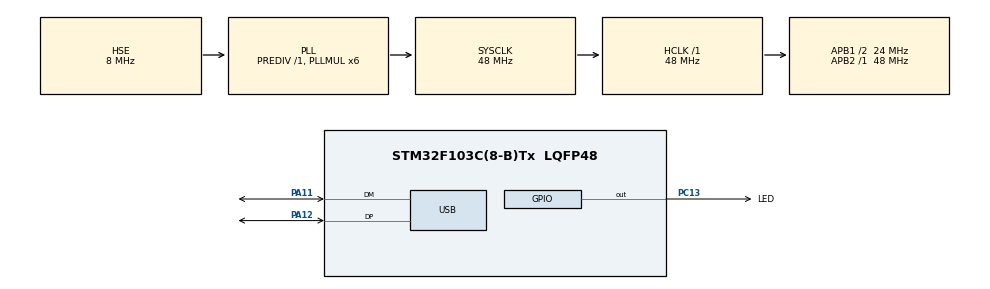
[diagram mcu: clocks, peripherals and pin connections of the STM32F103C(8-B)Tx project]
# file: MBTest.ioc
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Mcu.Family=STM32F1
Mcu.Name=STM32F103C(8-B)Tx
Mcu.Package=LQFP48
NVIC.PriorityGroup=NVIC_PRIORITYGROUP_4
NVIC.TIM4_IRQn=true\:0\:0\:false\:false\:true\:true\:true\:true
NVIC.USB_LP_CAN1_RX0_IRQn=true\:0\:0\:false\:false\:true\:false\:true\:true
PA11.Mode=Device
PA11.Signal=USB_DM
PA12.Mode=Device
PA12.Signal=USB_DP
PA13.Mode=Serial_Wire
PA13.Signal=SYS_JTMS-SWDIO
PA14.Mode=Serial_Wire
PA14.Signal=SYS_JTCK-SWCLK
PC13-TAMPER-RTC.GPIO_Label=LED
PC13-TAMPER-RTC.Signal=GPIO_Output
PC14-OSC32_IN.Mode=LSE-External-Oscillator
PC14-OSC32_IN.Signal=RCC_OSC32_IN
PC15-OSC32_OUT.Mode=LSE-External-Oscillator
PC15-OSC32_OUT.Signal=RCC_OSC32_OUT
PD0-OSC_IN.Mode=HSE-External-Oscillator
PD0-OSC_IN.Signal=RCC_OSC_IN
PD1-OSC_OUT.Mode=HSE-External-Oscillator
PD1-OSC_OUT.Signal=RCC_OSC_OUT
ProjectManager.HeapSize=0x200
ProjectManager.StackSize=0x400
ProjectManager.TargetToolchain=Makefile
RCC.AHBFreq_Value=48000000
RCC.APB1CLKDivider=RCC_HCLK_DIV2
RCC.APB1Freq_Value=24000000
RCC.APB1TimFreq_Value=48000000
RCC.APB2Freq_Value=48000000
RCC.APB2TimFreq_Value=48000000
RCC.HCLKFreq_Value=48000000
RCC.PLLMUL=RCC_PLL_MUL6
RCC.PLLSourceVirtual=RCC_PLLSOURCE_HSE
RCC.SYSCLKFreq_VALUE=48000000
RCC.SYSCLKSource=RCC_SYSCLKSOURCE_PLLCLK
RCC.USBFreq_Value=48000000
TIM4.AutoReloadPreload=TIM_AUTORELOAD_PRELOAD_ENABLE
TIM4.Period=9999
TIM4.Prescaler=47
USB_DEVICE.APP_RX_DATA_SIZE=256
USB_DEVICE.APP_TX_DATA_SIZE=256
USB_DEVICE.CLASS_NAME_FS=CDC
USB_DEVICE.VirtualMode=Cdc
USB_DEVICE.VirtualModeFS=Cdc_FS
VP_TIM4_VS_ClockSourceINT.Mode=Internal
VP_USB_DEVICE_VS_USB_DEVICE_CDC_FS.Mode=CDC_FS
board=custom

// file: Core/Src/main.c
/* USER CODE BEGIN Header */
/**
  ******************************************************************************
  * @file           : main.c
  * @brief          : Main program body
  ******************************************************************************
  * @attention
  *
  * <h2><center>&copy; Copyright (c) 2022 STMicroelectronics.
  * All rights reserved.</center></h2>
  *
  * This software component is licensed by ST under BSD 3-Clause license,
  * the "License"; You may not use this file except in compliance with the
  * License. You may obtain a copy of the License at:
  *                        opensource.org/licenses/BSD-3-Clause
  *
  ******************************************************************************
  */
/* USER CODE END Header */
#include "main.h"
#include "tim.h"
#include "usb_device.h"
#include "gpio.h"

/* USER CODE BEGIN Includes */
#include <string.h>
#include "fifo.h"
#include "mb-rtu.h"
#include "mb-table.h"
#include "usbd_cdc_if.h"
/* USER CODE END Includes */

/* USER CODE BEGIN PTD */

void send_data(uint8_t *Data,uint16_t Len)
{
  CDC_Transmit_FS(Data,Len);
  HAL_GPIO_TogglePin(LED_GPIO_Port,LED_Pin);
}

void add_random_data()
{
  int i;

  mb_table_write(TBALE_Coils,0,rand());
  mb_table_write(TBALE_Discretes_Input,0,rand());

  for(i=0;i<10;i++)
  {
    mb_table_write(TBALE_Input_Registers,i,rand());
  }

  for(i=0;i<10;i++)
  {
    mb_table_write(TABLE_Holding_Registers,i,rand());
  }

}

//Timeout Signal
void HAL_TIM_PeriodElapsedCallback(TIM_HandleTypeDef *htim)
{
  if(htim->Instance==TIM4)
  {
    HAL_TIM_Base_Stop_IT(&htim4);
    mb_rx_timeout_handler();

    //Add Some Data to Table
    add_random_data();
  }
}

void timeout_timer_reset()
{
  //Reset Timer
  TIM4->CNT=0;
  HAL_TIM_Base_Start_IT(&htim4);
}

/* USER CODE END PTD */

void SystemClock_Config(void);

int main(void)
{
  /* USER CODE BEGIN 1 */
  uint8_t Ch;
  /* USER CODE END 1 */

  /* MCU Configuration--------------------------------------------------------*/

  /* Reset of all peripherals, Initializes the Flash interface and the Systick. */
  HAL_Init();

  /* Configure the system clock */
  SystemClock_Config();

  /* USER CODE BEGIN SysInit */
  MX_GPIO_Init();
  /* USER CODE END SysInit */

  /* Initialize all configured peripherals */
  MX_GPIO_Init();
  MX_TIM4_Init();
  MX_USB_DEVICE_Init();
  /* USER CODE BEGIN 2 */
  FIFO_Init(64);
  mb_set_tx_handler(&send_data);
  /* USER CODE END 2 */

  /* Infinite loop */
  /* USER CODE BEGIN WHILE */

  while (1)
  {
    while(FIFO_Read(&Ch)==FIFO_OK)
    {
      mb_rx_new_data(Ch);
      timeout_timer_reset();
    }
    /* USER CODE END WHILE */

  }
}

void SystemClock_Config(void)
{
  RCC_OscInitTypeDef RCC_OscInitStruct = {0};
  RCC_ClkInitTypeDef RCC_ClkInitStruct = {0};
  RCC_PeriphCLKInitTypeDef PeriphClkInit = {0};

  /** Initializes the RCC Oscillators according to the specified parameters
  * in the RCC_OscInitTypeDef structure.
  */
  RCC_OscInitStruct.OscillatorType = RCC_OSCILLATORTYPE_HSE;
  RCC_OscInitStruct.HSEState = RCC_HSE_ON;
  RCC_OscInitStruct.HSEPredivValue = RCC_HSE_PREDIV_DIV1;
  RCC_OscInitStruct.HSIState = RCC_HSI_ON;
  RCC_OscInitStruct.PLL.PLLState = RCC_PLL_ON;
  RCC_OscInitStruct.PLL.PLLSource = RCC_PLLSOURCE_HSE;
  RCC_OscInitStruct.PLL.PLLMUL = RCC_PLL_MUL6;
  if (HAL_RCC_OscConfig(&RCC_OscInitStruct) != HAL_OK)
  {
    Error_Handler();
  }

  /** Initializes the CPU, AHB and APB buses clocks
  */
  RCC_ClkInitStruct.ClockType = RCC_CLOCKTYPE_HCLK|RCC_CLOCKTYPE_SYSCLK
                              |RCC_CLOCKTYPE_PCLK1|RCC_CLOCKTYPE_PCLK2;
  RCC_ClkInitStruct.SYSCLKSource = RCC_SYSCLKSOURCE_PLLCLK;
  RCC_ClkInitStruct.AHBCLKDivider = RCC_SYSCLK_DIV1;
  RCC_ClkInitStruct.APB1CLKDivider = RCC_HCLK_DIV2;
  RCC_ClkInitStruct.APB2CLKDivider = RCC_HCLK_DIV1;

  if (HAL_RCC_ClockConfig(&RCC_ClkInitStruct, FLASH_LATENCY_1) != HAL_OK)
  {
    Error_Handler();
  }
  PeriphClkInit.PeriphClockSelection = RCC_PERIPHCLK_USB;
  PeriphClkInit.UsbClockSelection = RCC_USBCLKSOURCE_PLL;
  if (HAL_RCCEx_PeriphCLKConfig(&PeriphClkInit) != HAL_OK)
  {
    Error_Handler();
  }
}

void Error_Handler(void)
{
  __disable_irq();
  while (1)
  {
  }
}
